# M55M1 register map
File version: 1.0
Registers are 32-bit, read-write, reset 0x0 unless marked. A register's access mark holds for its fields unless they carry their own. Offsets are from the block's base; [hi:lo] are bit positions; {n}, {i} and the like mark numbered series; 'fields as' and 'values as' point back to an identical list.

## SYS (part 1 of 3) — SYS Register Map
Base 0x40000000
0x00 SYS_PDID ro reset 0x551000 — Part Device Identification Number Register
  [31:0] PDID — Part Device Identification Number (Read Only). This register reflects device part number code. Software can read this register to identify which device is used.
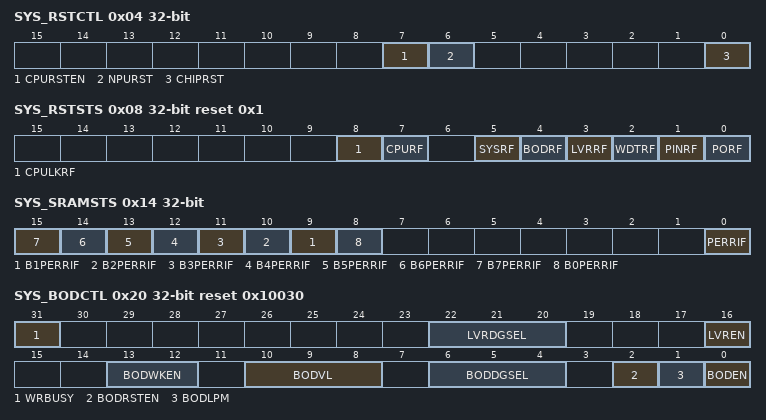
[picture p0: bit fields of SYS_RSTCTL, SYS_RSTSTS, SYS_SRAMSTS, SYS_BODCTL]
0x04 SYS_RSTCTL — System Reset Control Register
  [7] CPURSTEN — Processor Core Reset Enable (Write Protect). Setting this bit will only reset the processor core and Flash Memory Controller(FMC) when CPU execute WFI instruction. Note: This bit is write protected. Refer to the SYS_REGLCTL register..
    0=Processor core not reset when execute WFI instruction; 1=Processor core reset when execute WFI instruction
  [6] NPURST — NPU Reset (Write Protect). Setting this bit to 1 will generate a reset signal to the NPU. User needs to set this bit to 0 to release from reset state. Note 1: This bit is write protected. Refer to the SYS_REGLCTL register. Note 2: This bit is not retained when D0 power is turned off.
    0=NPU controller normal operation; 1=NPU controller reset
  [0] CHIPRST — Chip One-shot Reset (Write Protect). Setting this bit will reset the whole chip, including Processor core and all peripherals, and this bit will automatically return to 0 after the 2 clock cycles. The CHIPRST is same as the POR reset, all the chip controllers is reset and the chip setting from Flash are also reload. About the difference between CHIPRST and SYSRESETREQ(AIRCR[2]), please refer to section 6.2.2. Note: This bit is write protected. Refer to the SYS_REGLCTL register.
    0=Chip normal operation; 1=Chip one-shot reset
0x08 SYS_RSTSTS reset 0x1 — System Reset Status Register
  [8] CPULKRF — CPU Lockup Reset Flag. The CPU Lockup reset flag is set by hardware if Cortex-M55 lockup happened. Note 1: Write 1 to clear this bit to 0. Note 2: When CPU lockup happened under ICE is connected, this flag will set to 1 but chip will not reset. Note 3: This bit is not retained when D0 power is turned off.
    0=No reset from CPU lockup happened; 1=The Cortex-M55 lockup happened and chip is reset
  [7] CPURF — CPU Reset Flag. The CPU reset flag is set by hardware if software writes CPURST (SYS_RSTCTL[7]) 1 to reset the Cortex-M55 core and Flash Memory Controller (FMC). Note 1: Write 1 to clear this bit to 0. Note 2: This bit is not retained when D0 power is turned off.
    0=No reset from CPU; 1=The Cortex-M55 core and FMC are reset by software setting CPURST to 1
  [5] SYSRF — System Reset Flag. The system reset flag is set by the 'Reset Signal' from the Cortex-M55 core to indicate the previous reset source. Note 1: Write 1 to clear this bit to 0. Note 2: This bit is not retained when D0 power is turned off.
    0=No reset from the Cortex-M55; 1=The Cortex-M55 had issued the reset signal to reset the system by writing 1 to the bit SYSRESETREQ(AIRCR[2], Application Interrupt and Reset Control Register, address = 0xE000ED0C) in system control registers of Cortex-M55 core
  [4] BODRF — BOD Reset Flag. The BOD reset flag is set by the 'Reset Signal' from the Brown-out Detector to indicate the previous reset source. Note 1: Write 1 to clear this bit to 0. Note 2: This bit is not retained when D3 power is turned off.
    0=No reset from BOD; 1=The BOD had issued the reset signal to reset the system
  [3] LVRRF — LVR Reset Flag. The LVR reset flag is set by the 'Reset Signal' from the Low Voltage Reset Controller to indicate the previous reset source. Note 1: Write 1 to clear this bit to 0. Note 2: This bit is not retained when D3 power is turned off.
    0=No reset from LVR; 1=The LVR controller had issued the reset signal to reset the system
  [2] WDTRF — WDT Reset Flag. The WDT reset flag is set by the 'Reset Signal' from the Watchdog Timer or Window Watchdog Timer to indicate the previous reset source. Note 1: Write 1 to clear this bit to 0. Note 2: This bit is not retained when D2 power is turned off. Note 3: Watchdog Timer register RSTF(WDT_CTL[2]) bit is set if the system has been reset by WDT time-out reset. Window Watchdog Timer register WWDTRF(WWDT_STATUS[1]) bit is set if the system has been reset by WWDT time-out reset. Note 4: Extra Watchdog Timer register RSTF(EWDT_CTL[2]) bit is set if the system has been reset by EWDT time-out reset. Extra Window Watchdog Timer register WWDTRF(EWWDT_STATUS[1]) bit is set if the system has been reset by EWWDT time-out reset.
    0=No reset from watchdog timer or window watchdog timer; 1=The watchdog timer or window watchdog timer had issued the reset signal to reset the system
  [1] PINRF — nRESET Pin Reset Flag. The nRESET pin reset flag is set by the 'Reset Signal' from the nRESET Pin to indicate the previous reset source. Note 1: Write 1 to clear this bit to 0. Note 2: This bit is not retained when D4 power is turned off.
    0=No reset from nRESET pin; 1=Pin nRESET had issued the reset signal to reset the system
  [0] PORF — POR Reset Flag. The POR reset flag is set by the 'Reset Signal' from the Power-on Reset (POR) Controller or bit CHIPRST (SYS_RSTCTL[0]) to indicate the previous reset source. Note 1: Write 1 to clear this bit to 0. Note 2: This bit is not retained when D0 power is turned off.
    0=No reset from POR or CHIPRST; 1=Power-on Reset (POR) or CHIPRST had issued the reset signal to reset the system
0x0C SYS_VTORSET reset 0x100000 — VTOR Setting Register
  [31:7] VTORSET — VTOR Setting After SPD Wakeup (Write Protect). The value will be loaded to Vector Table Offset Register, which is at the address 0xE000ED08, when chip wake up and Perfomace Domain be turn off. Note 1: These bits are write protected. Refer to the SYS_REGLCTL register. Note 2: These bits are not retained when D4 power is turned off.
0x10 SYS_SRAMICTL — System SRAM Parity Error Interrupt Enable Control Register
  [0] PERRIEN — SRAM Parity Check Error Interrupt Enable Bit. Note: This bit is not retained when D0 power is turned off.
    0=SRAM parity check error interrupt Disabled; 1=SRAM parity check error interrupt Enabled
0x14 SYS_SRAMSTS (reset mask 0xFFFFFFF0) — System SRAM Parity Check Status Register
  [n+8] B{n}PERRIF ro (n=1..7) — SRAM Byte {n} Parity Check Error Flag (Read Only). This bit indicates the System SRAM byte {n} parity error occurred. Note 1: Write 1 to PERRIF for clear this bit to 0. Note 2: The default value depends on the content of SRAM. It is better to check this value before use it. If the default value is 1, it shall be cleared first. Note 3: This bit is not retained when D0 power is turned off.
    0=No System SRAM byte {n} parity error; 1=System SRAM byte {n} parity error occured
  [8] B0PERRIF ro — SRAM Byte 0 Parity Check Error Flag (Read Only). This bit indicates the System SRAM byte 0 parity error occurred. Note 1: Write 1 to PERRIF for clear this bit to 0.. Note 2: The default value depends on the content of SRAM. It is better to check this value before use it. If the default value is 1, it shall be cleared first. Note 3: This bit is not retained when D0 power is turned off.
    0=No System SRAM byte 0 parity error; 1=System SRAM byte 0 parity error occured
  [0] PERRIF — SRAM Parity Check Error Flag. This bit indicates the System SRAM byte 0 parity error occurred. Note 1: Write 1 to clear this bit to 0. Note 2: The default value depends on the content of SRAM. It is better to check this value before use it. If the default value is 1, it shall be cleared first. Note 3: This bit is not retained when D0 power is turned off.
    0=No System SRAM parity error; 1=System SRAM parity error occured
0x18 SYS_SRAMEADR ro — System SRAM Parity Error Address Register
  [31:0] ERRADDR — System SRAM Parity Error Address (Read Only). This register shows system SRAM parity error byte offset. Note: These bits are not retained when D0 power is turned off.
0x20 SYS_BODCTL reset 0x10030 — Brown-out Detector Control Register
  [31] WRBUSY ro — Write Busy Flag (Read Only). If SYS_BODCTL is written, this bit is asserted automatically by hardware, and is de-asserted when write procedure is finished.
    0=SYS_BODCTL register is ready for write operation; 1=SYS_BODCTL register is busy on the last write operation. Other write operations are ignored
  [22:20] LVRDGSEL — LVR Output De-glitch Time Select (Write Protect). Note 1: These bits are write protected. Refer to the SYS_REGLCTL register. Note 2: These bits are not retained when D0 power is turned off. Note 3: Because SCLK is invalid in Power-down mode, the de-glitch time must change to without de-glitch before system enters Power-down mode.
    0=Without de-glitch function; 1=4 system clock (SCLK); 2=8 system clock (SCLK); 3=16 system clock (SCLK); 4=32 system clock (SCLK); 5=64 system clock (SCLK); 6=128 system clock (SCLK); 7=256 system clock (SCLK)
  [16] LVREN — Low Voltage Reset Enable Bit (Write Protect). The LVR function resets the chip when the input power voltage is lower than LVR circuit setting. LVR function is enabled by default. Note 1: After enabling the bit, the LVR function will be active with 200us delay for LVR output stable (default). Note 2: This bit is write protected. Refer to the SYS_REGLCTL register. Note 3: Write operation is ignored when WRBUSY is high. Note 4: This bit is not retained when D3 power is turned off.
    0=Low Voltage Reset function Disabled; 1=Low Voltage Reset function Enabled
  [13:12] BODWKEN — Brown-out Detector Wake-Up Selection (Write Protect). Note 1: These bits are write protected. Refer to the SYS_REGLCTL register. Note 2: Write operation is ignored when WRBUSY is high. Note 3: These bits are not retained when D3 power is turned off.
    0=Brown-out Detector wake-up function Disable; 1=Brown-out Detector power rise wake-up function Enable; 2=Brown-out Detector power drop wake-up function Enable; 3=Brown-out Detector power rise and drop wake-up function Enable
  [10:8] BODVL — Brown-out Detector Threshold Voltage Selection (Write Protect). The default value is set by Flash controller user configuration register CBOV (CONFIG0 [23:21]). Note 1: These bits are write protected. Refer to the SYS_REGLCTL register. Note 2: Write operation is ignored when WRBUSY is high. Note 3: These bits are not retained when D3 power is turned off. Note 4: The default value is set by UCFG0[23:21].
    0=Brown-out Detector threshold voltage is 1.6V; 1=Brown-out Detector threshold voltage is 1.8V; 2=Brown-out Detector threshold voltage is 2.0V; 3=Brown-out Detector threshold voltage is 2.2V; 4=Brown-out Detector threshold voltage is 2.4V; 5=Brown-out Detector threshold voltage is 2.6V; 6=Brown-out Detector threshold voltage is 2.8V; 7=Brown-out Detector threshold voltage is 3.0V
  [6:4] BODDGSEL — Brown-out Detector Output De-glitch Time Select (Write Protect). Note 1: These bits are write protected. Refer to the SYS_REGLCTL register. Note 2: Write operation is ignored when WRBUSY is high. Note 3: These bits are not retained when D0 power is turned off. Note 4: Because SCLK is invalid in Power-down mode, the de-glitch time must change to LIRC before system enters Power-down mode. Note 5: If BODLPM(SYS_BODCTL[1]) is 1, the Brown-out Detector Output de-glitch circuit always uses LIRC clock even if BODDGSEL is not 000.
    0=BOD output is sampled by LIRC clock; 1=4 system clock (SCLK); 2=8 system clock (SCLK); 3=16 system clock (SCLK); 4=32 system clock (SCLK); 5=64 system clock (SCLK); 6=128 system clock (SCLK); 7=256 system clock (SCLK)
  [2] BODRSTEN — Brown-out Reset Enable Bit (Write Protect). The default value is set by Flash controller user configuration register CBORST(CONFIG0[20]) bit. Note 1: When the Brown-out Detector function is enabled (BODEN high) and BOD reset function is enabled (BODRSTEN high), BOD will assert a signal to reset chip when the detected voltage is lower than the threshold (BODOUT high). When the BOD function is enabled (BODEN high) and BOD interrupt function is enabled (BODRSTEN low), BOD will assert an interrupt if AVDD is lower than BODVL, BOD interrupt will keep till the BODIF set to 0. BOD interrupt can be blocked by disabling the NVIC BOD interrupt or disabling BOD function (setting BODEN low). Note 2: This bit is write protected. Refer to the SYS_REGLCTL register. Note 3: This bit is not retained when D3 power is turned off. Note 4: Write operation is ignored when WRBUSY is high. Note 5: The default value is set by inverse UCFG0[20]. Note 6: If D2PGEN(PMC_PWRCTL[2]) is 1 and enters Power-down mode, the brown-out reset function always keeps enabled even if BODRSTEN is 0.
    0=Brown-out 'INTERRUPT' function Enabled; 1=Brown-out 'RESET' function Enabled
  [1] BODLPM — Brown-out Detector Low Power Mode (Write Protect). Note 1: The BOD consumes about 10uA in normal mode, the low power mode can reduce the current to about 1/10 but slow the BOD response. Note 2: This bit is write protected. Refer to the SYS_REGLCTL register. Note 3: Write operation is ignored when WRBUSY is high. Note 4: This bit is not retained when D3 power is turned off.
    0=BOD operated in normal mode (default); 1=BOD Low Power mode Enabled
  [0] BODEN — Brown-out Detector Enable Bit (Write Protect). The default value is set by Flash controller user configuration register CBODEN (CONFIG0 [19]). Note 1: This bit is write protected. Refer to the SYS_REGLCTL register. Note 2: Write operation is ignored when WRBUSY is high. Note 3: This bit is not retained when D3 power is turned off. Note 4: The default value is set by inverse UCFG0[19].
    0=Brown-out Detector function Disabled; 1=Brown-out Detector function Enabled
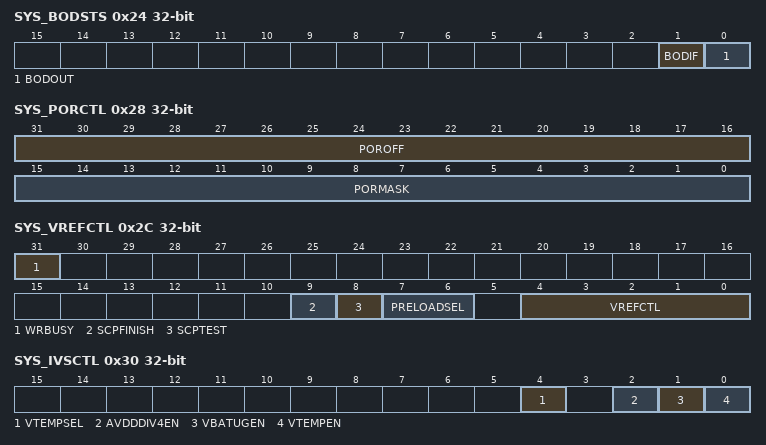
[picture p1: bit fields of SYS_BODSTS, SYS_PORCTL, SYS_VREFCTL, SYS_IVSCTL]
0x24 SYS_BODSTS — Brown-out Detector Status Register
  [1] BODIF — Brown-out Detector Interrupt Flag. Note 1: Write 1 to clear this bit to 0. Note 2: This bit is not retained when D1 power is turned off.
    0=Brown-out Detector does not detect any voltage draft at VDD down through or up through the voltage of BODVL(SYS_BODCTL[10:8]) setting; 1=When Brown-out Detector detects the VDD is dropped down through the voltage of BODVL(SYS_BODCTL[10:8]) setting or the VDD is raised up through the voltage of BODVL(SYS_BODCTL[10:8]) setting, this bit is set to 1 and the brown-out interrupt is requested if brown-out interrupt is enabled
  [0] BODOUT ro — Brown-out Detector Output Status (Read Only). It means the detected voltage is lower than BODVL(SYS_BODCTL[10:8]) setting. If the BODEN is 0, BOD function disabled, this bit always responds 0.
    0=Brown-out Detector output status is 0; 1=Brown-out Detector output status is 1
0x28 SYS_PORCTL — Power-on Reset Controller Register
  [31:16] POROFF — Power-on Reset Enable Bit (Write Protect). When powered on, the POR circuit generates a reset signal to reset the whole chip function, but noise on the power may cause the POR active again. User can disable internal POR circuit to avoid unpredictable noise to cause chip reset by writing 0x5AA5 to this field. The POR function will be active again when this field is set to another value or chip is reset by other reset source, including: nRESET, Watchdog, LVR reset, BOD reset, ICE reset command and the software-chip reset function. Note 1: These bits are write protected. Refer to the SYS_REGLCTL register. Note 2: These bits are not retained when D3 power is turned off.
  [15:0] PORMASK — Power-on Reset Mask Enable Bit (Write Protect). When powered on, the POR circuit generates a reset signal to reset the whole chip function, but noise on the power may cause the POR active again. User can mask internal POR signal to avoid unpredictable noise to cause chip reset by writing 0x5AA5 to this field. The POR function will be active again when this field is set to another value or chip is reset by other reset source, including: nRESET, Watchdog, LVR reset, BOD reset, ICE reset command and the software-chip reset function. Note 1: These bits are write protected. Refer to the SYS_REGLCTL register. Note 2: These bits are not retained when D3 power is turned off.
0x2C SYS_VREFCTL — VREF Control Register
  [31] WRBUSY ro — Write Busy Flag (Read Only). If SYS_VREFCTL is written, this bit is asserted automatically by hardware, and is de-asserted when write procedure is finished.
    0=SYS_VREFCTL register is ready for write operation; 1=SYS_VREFCTL register is busy on the last write operation. Other write operations are ignored
  [9] SCPFINISH ro — Short Circuit Protection Result (Read Only). Short circuit protection finish.
  [8] SCPTEST — Short Circuit Protection Test Pin (Write Protect). Note 1: This bit is write protected. Refer to the SYS_REGLCTL register. Note 2: Write operation is ignored when WRBUSY is high. Note 3: These bits are not retained when D2 power is turned off.
    0=Short circuit protection Disabled; 1=Short circuit protection Enabled
  [7:6] PRELOADSEL — Pre-load Timing Selection (Write Protect). Note 1: These bits are write protected. Refer to the SYS_REGLCTL register. Note 2: Write operation is ignored when WRBUSY is high. Note 3: These bits are not retained when D2 power is turned off.
    0=pre-load time is 480us for 1uF Capacitor, initial = 0v; 1=pre-load time is 2ms for 4.7uF Capacitor, initial = 0v; 2=pre-load time is 3ms for 1uF Capacitor, initial = 3.6v; 3=pre-load time is 15ms for 4.7uF Capacitor, initial = 3.6v
  [4:0] VREFCTL — VREF Control Bits (Write Protect). Note 1: These bits are write protected. Refer to the SYS_REGLCTL register. Note 2: Write operation is ignored when WRBUSY is high. Note 3: These bits are not retained when D2 power is turned off.
    0=VREF is from external pin; 3=VREF is internal 1.6V; 7=VREF is internal 2.048V; 11=VREF is internal 2.500V; 15=VREF is internal 3.072V
0x30 SYS_IVSCTL — Internal Voltage Source Control Register
  [4] VTEMPSEL — Temperature Sensor Slope Select Bit. This bit is used to select temperature sensor slope trend. Note 2: These bits are not retained when D0 power is turned off.
    0=Temperature sensor CTAT slope; 1=Temperature sensor PTAT slope
  [2] AVDDDIV4EN — AVDD divide 4 Enable Bit. This bit is used to enable/disable AVDD divide 4 function. Note 1: After this bit is set to 1, the value of AVDD divide 4 output voltage can be obtained from ADC conversion result. Note 2: These bits are not retained when D2 power is turned off.
    0=AVDD divide 4 function Disabled (default); 1=AVDD divide 4 function Enabled
  [1] VBATUGEN — VBAT Unity Gain Buffer Enable Bit. This bit is used to enable/disable VBAT unity gain buffer function. Note: After this bit is set to 1, the value of VBAT unity gain buffer output voltage can be obtained from ADC conversion result.
    0=VBAT unity gain buffer function Disabled (default); 1=VBAT unity gain buffer function Enabled
  [0] VTEMPEN — Temperature Sensor Enable Bit. This bit is used to enable/disable temperature sensor function. Note 1: After this bit is set to 1, the value of temperature sensor output can be obtained from ADC conversion result. Please refer to ADC chapter for details. Note 2: This bit is not retained when D0 power is turned off.
    0=Temperature sensor function Disabled (default); 1=Temperature sensor function Enabled
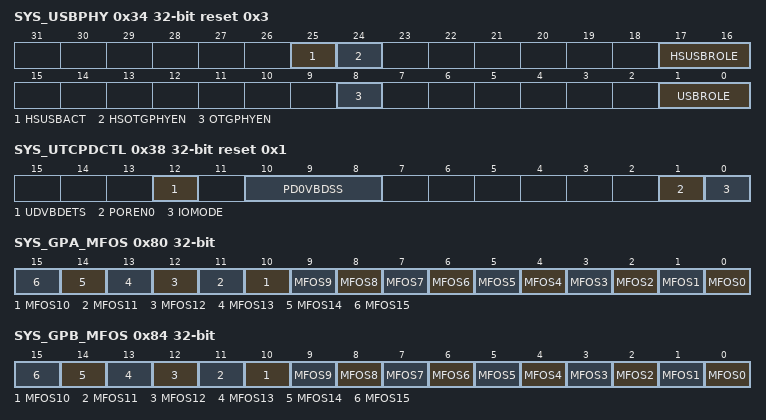
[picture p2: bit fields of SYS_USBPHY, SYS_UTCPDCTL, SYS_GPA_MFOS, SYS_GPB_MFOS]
0x34 SYS_USBPHY reset 0x3 — USB PHY Control Register
  [25] HSUSBACT — HSOTG PHY Active Control. This bit is used to control HSOTG PHY at reset state or active state. Note: After setting HSOTGPHYEN (SYS_USBPHY[24]) to enable HSOTG PHY, user should keep HSOTG PHY at reset mode at lease 10us before changing to active mode.
    0=HSOTG PHY at reset state; 1=HSOTG PHY at active state
  [24] HSOTGPHYEN — HSUSB OTG PHY Enable (Write Protect). This bit is used to enable/disable HSOTG PHY function. Note 1: This bit is write protected. Refer to the SYS_REGLCTL register. Note 2: This bit is not retained when D1 power is turned off.
    0=HSUSB OTG PHY function Disabled (default); 1=HSUSB OTG PHY function Enabled
  [17:16] HSUSBROLE — HSUSB Role Option (Write Protect). These two bits are used to select the role of HSUSB. Note 1: These bits are write protected. Refer to the SYS_REGLCTL register. Note 2: These bits are not retained when D1 power is turned off.
    0=Standard HSUSB Device mode; 1=Standard HSUSB Host mode; 2=ID dependent mode; 3=On-The-Go device mode
  [8] OTGPHYEN — USB OTG PHY Enable (Write Protect). This bit is used to enable/disable OTG PHY function. Note: This bit is not retained when D1 power is turned off.
    0=OTG PHY function Disabled (default); 1=OTG PHY function Enabled
  [1:0] USBROLE — USB Role Option (Write Protect). These two bits are used to select the role of USB. Note 1: These bits are write protected. Refer to the SYS_REGLCTL register. Note 2: These bits are not retained when D1 power is turned off.
    0=Standard USB Device mode; 1=Standard USB Host mode; 2=ID dependent mode; 3=On-The-Go device mode
0x38 SYS_UTCPDCTL reset 0x1 — UTCPD Control Register
  [12] UDVBDETS — UDC11 VBUS Detect Source Select. Note 1: Before use UDC11 function, UDVBDETS should be set and cannot change during UDC11 operating. Note 2: This bit is not retained when D3 power is turned off.
    0=UDC11 VBUS detect source from OTGPHY; 1=UDC11 VBUS detect source from VBDETSW0
  [10:8] PD0VBDSS — UTCPD0 VBUS Detect Source Select. UTCPD0 controller need a VBUS detect result to note if VBUS is connected. For NPD0~2 usage, ACMP can be another voltage detect method to detect VBUS pulg in or out. This bit field is used to select UTCPD0 VBUS detect source. And the selected result is VBDETSW0. Note 1: Before use UTCPD0 function, UDVBDETS should be set and cannot change during UTCPD0 operating. Note 2: This bit is not retained when D3 power is turned off.
    0=UTCPD0 VBUS detect source from UTCPD0 PHY; 1=UTCPD0 VBUS detect source from ACMP0 output; 2=UTCPD0 VBUS detect source from ACMP1 output; 3=UTCPD0 VBUS detect source from ACMP2 output
  [1] POREN0 — UTCPD0 Power-on Enable Bit. Note 1: user should set POREN0 to 1 after IOMODE is setting down. Note 2: This bit is not retained when D4 power is turned off.
    0=UTCPD0 PHY in reset mode; 1=UTCPD0 PHY in normal mode
  [0] IOMODE — UTCPD0 as I/O mode. This bit is used to define UTCPD0 CCx and CCDBx function. Note: This bit is not retained when D4 power is turned off.
    0=Pin as UTCPD0 CCx and CCDBx function; 1=Pin as general I/O function
0x40 SYS_DBUSCTL reset 0x1 — Data Bus Control Register
  [0] H2XBSTEN — Burst AHB2AXI Bridge access Enable Bit (Write Protect). Note 1: These bits are write protected. Refer to the SYS_REGLCTL register. Note 2: This bit is not retained when D0 power is turned off.
    0=Normal operating; 1=Force the attribute of all access from AHB to AXI modifiable
0x80 SYS_GPA_MFOS — GPIOA Multiple Function Output Select Register
  [all] fields
    0=Multiple function pin output mode type is Push-pull mode; 1=Multiple function pin output mode type is Open-drain mode
  [n] MFOS{n} (n=0..15) — GPIOA Pin[x] Multiple Function Pin Output Mode Select. This bit used to select multiple function pin output mode type for PA.x pin. Note 1: These bits are not retained when D2 power is turned off.
0x84 SYS_GPB_MFOS — GPIOB Multiple Function Output Select Register
  [all] fields
    values as the fields of SYS_GPA_MFOS
  [n] MFOS{n} (n=0..15) — GPIOB Pin[x] Multiple Function Pin Output Mode Select. This bit used to select multiple function pin output mode type for PB.x pin. Note: These bits are not retained when D2 power is turned off.
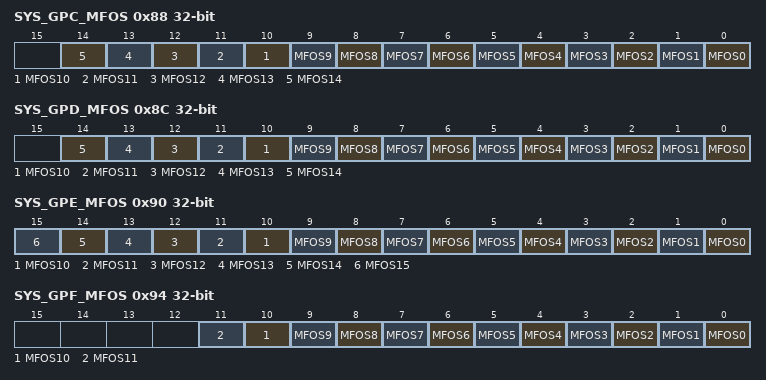
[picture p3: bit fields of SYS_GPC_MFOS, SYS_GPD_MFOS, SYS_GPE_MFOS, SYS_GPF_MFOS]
0x88 SYS_GPC_MFOS — GPIOC Multiple Function Output Select Register
  [all] fields
    values as the fields of SYS_GPA_MFOS
  [n] MFOS{n} (n=0..14) — GPIOC Pin[x] Multiple Function Pin Output Mode Select. This bit used to select multiple function pin output mode type for PC.x pin. Note: These bits are not retained when D2 power is turned off.
0x8C SYS_GPD_MFOS — GPIOD Multiple Function Output Select Register
  [all] fields
    values as the fields of SYS_GPA_MFOS
  [n] MFOS{n} (n=0..14) — GPIOD Pin[x] Multiple Function Pin Output Mode Select. This bit used to select multiple function pin output mode type for PD.x pin. Note: These bits are not retained when D2 power is turned off.
0x90 SYS_GPE_MFOS — GPIOE Multiple Function Output Select Register
  [all] fields
    values as the fields of SYS_GPA_MFOS
  [n] MFOS{n} (n=0..15) — GPIOE Pin[x] Multiple Function Pin Output Mode Select. This bit used to select multiple function pin output mode type for PE.x pin. Note: These bits are not retained when D2 power is turned off.
0x94 SYS_GPF_MFOS — GPIOF Multiple Function Output Select Register
  [all] fields
    values as the fields of SYS_GPA_MFOS
  [n] MFOS{n} (n=0..11) — GPIOF Pin[x] Multiple Function Pin Output Mode Select. This bit used to select multiple function pin output mode type for PF.x pin. Note: These bits are not retained when D2 power is turned off.
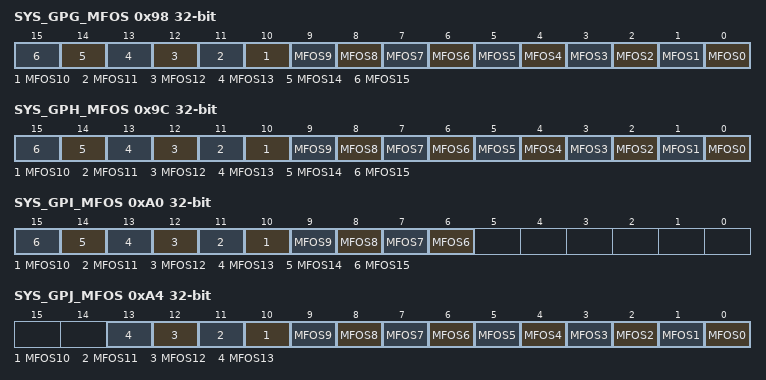
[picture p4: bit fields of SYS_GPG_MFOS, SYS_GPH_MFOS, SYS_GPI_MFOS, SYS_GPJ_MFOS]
0x98 SYS_GPG_MFOS — GPIOG Multiple Function Output Select Register
  [all] fields
    values as the fields of SYS_GPA_MFOS
  [n] MFOS{n} (n=0..15) — GPIOG Pin[x] Multiple Function Pin Output Mode Select. This bit used to select multiple function pin output mode type for PG.x pin. Note: These bits are not retained when D2 power is turned off.
0x9C SYS_GPH_MFOS — GPIOH Multiple Function Output Select Register
  [all] fields
    values as the fields of SYS_GPA_MFOS
  [n] MFOS{n} (n=0..15) — GPIOH Pin[x] Multiple Function Pin Output Mode Select. This bit used to select multiple function pin output mode type for PH.x pin. Note: These bits are not retained when D2 power is turned off.
0xA0 SYS_GPI_MFOS — GPIOI Multiple Function Output Select Register
  [all] fields
    values as the fields of SYS_GPA_MFOS
  [n] MFOS{n} (n=6..15) — GPIOI Pin[x] Multiple Function Pin Output Mode Select. This bit used to select multiple function pin output mode type for PI.x pin. Note: These bits are not retained when D2 power is turned off.
0xA4 SYS_GPJ_MFOS — GPIOJ Multiple Function Output Select Register
  [all] fields
    values as the fields of SYS_GPA_MFOS
  [n] MFOS{n} (n=0..13) — GPIOJ Pin[x] Multiple Function Pin Output Mode Select. This bit used to select multiple function pin output mode type for PJ.x pin. Note: These bits are not retained when D2 power is turned off.
0x100 SYS_REGLCTL — Register Lock Control Register
  [7:0] REGLCTL — Register Lock Control Code. Some registers have write-protection function. Writing these registers have to disable the protected function by writing the sequence value '59h', '16h', '88h' to this field. After this sequence is completed, the REGLCTL bit will be set to 1 and write-protection registers can be normal write. REGLCTL[0]. Register Lock Control Disable Index. Note: These bits are not retained when D2 power is turned off.
    0=Write-protection Enabled for writing protected registers. Any write to the protected register is ignored; 1=Write-protection Disabled for writing protected registers
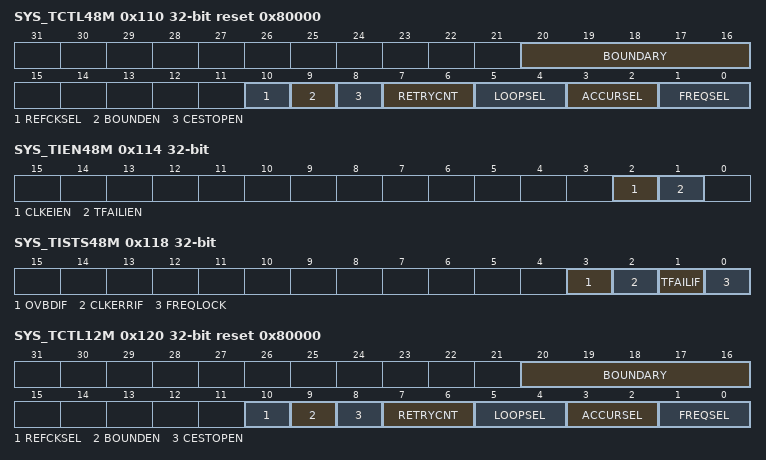
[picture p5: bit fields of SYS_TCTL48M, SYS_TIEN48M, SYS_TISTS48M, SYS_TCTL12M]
0x110 SYS_TCTL48M reset 0x80000 — HIRC 48M Trim Control Register
  [20:16] BOUNDARY — Boundary Selection. Fill the boundary range from 0x1 to 0x1F, 0x0 is reserved. Note: This field is effective only when the BOUNDEN(SYS_TCTL48M [9]) is enabled.
  [10] REFCKSEL — Reference Clock Selection
    0=HIRC48M trim reference clock is from external 32.768 kHz crystal oscillator; 1=HIRC48M trim reference clock is from internal USB synchronous mode
  [9] BOUNDEN — Boundary Enable Bit
    0=Boundary function Disabled; 1=Boundary function Enabled
  [8] CESTOPEN — Clock Error Stop Enable Bit
    0=Trim operation is kept going if clock is inaccurate; 1=Trim operation is stopped if clock is inaccurate
  [7:6] RETRYCNT — Trim Value Update Limitation Count. This field defines that how many times the auto trim circuit will try to update the HIRC48M trim value before the frequency of HIRC48M locked. Once the HIRC48M locked, the internal trim value update counter will be reset. If the trim value update counter reached this limitation value and frequency of HIRC48M is still not locked, the auto trim operation will be disabled and FREQSEL will be cleared to 00.
    0=Trim retry count limitation is 64 loops; 1=Trim retry count limitation is 128 loops; 2=Trim retry count limitation is 256 loops; 3=Trim retry count limitation is 512 loops
  [5:4] LOOPSEL — Trim Calculation Loop Selection. This field defines that trim value calculation is based on how many reference clocks. Note: For example, if LOOPSEL is set as 00, auto trim circuit will calculate trim value based on the average frequency difference in 4 clocks of reference clock.
    0=Trim value calculation is based on average difference in 4 clocks of reference clock; 1=Trim value calculation is based on average difference in 8 clocks of reference clock; 2=Trim value calculation is based on average difference in 16 clocks of reference clock; 3=Trim value calculation is based on average difference in 32 clocks of reference clock
  [3:2] ACCURSEL — Trim Accuracy Selection. This field indicates the target frequency accuracy of 48 MHz internal high speed RC oscillator (HIRC48M) auto trim.
    0=Accuracy is +-0.25% deviation within all temperature ranges; 1=Accuracy is +-0.50% deviation within all temperature ranges; 2=Accuracy is +-0.75% deviation within all temperature ranges; 3=Accuracy is +-1% deviation within all temperature ranges
  [1:0] FREQSEL — Trim Frequency Selection. This field indicates the target frequency of 48 MHz internal high speed RC oscillator (HIRC48M) auto trim. During auto trim operation, if clock error detected with CESTOPEN is set to 1 or trim retry limitation count reached, this field will be cleared to 00 automatically.
    0=Disable HIRC48M auto trim function; 1=Enable HIRC48M auto trim function and trim HIRC48M to 48 MHz
0x114 SYS_TIEN48M — HIRC 48M Trim Interrupt Enable Register
  [2] CLKEIEN — Clock Error Interrupt Enable Bit. This bit controls if CPU would get an interrupt while clock is inaccuracy during auto trim operation. If this bit is set to1, and CLKERRIF(SYS_TISTS48M [2]) is set during auto trim operation, an interrupt will be triggered to notify the clock frequency is inaccuracy.
    0=Disable CLKERRIF(SYS_TISTS48M [2]) status to trigger an interrupt to CPU; 1=Enable CLKERRIF(SYS_TISTS48M [2]) status to trigger an interrupt to CPU
  [1] TFAILIEN — Trim Failure Interrupt Enable Bit. This bit controls if an interrupt will be triggered while HIRC48M trim value update limitation count reached and HIRC48M frequency still not locked on target frequency set by FREQSEL(SYS_TCTL48M[1:0]). If this bit is high and TFAILIF(SYS_TSTS48M [1]) is set during auto trim operation, an interrupt will be triggered to notify that HIRC48M trim value update limitation count was reached.
    0=Disable TFAILIF(SYS_TISTS48M [1]) status to trigger an interrupt to CPU; 1=Enable TFAILIF(SYS_TISTS48M[1]) status to trigger an interrupt to CPU
0x118 SYS_TISTS48M — HIRC 48M Trim Interrupt Status Register
  [3] OVBDIF — Over Boundary Status. When the over boundary function is set, if there occurs the over boundary condition, this flag will be set. This is a status bit and doesn't trigger any interrupt. Note: Write 1 to clear this bit to 0.
    0=Over boundary condition did not occur; 1=Over boundary condition occurred
  [2] CLKERRIF — Clock Error Interrupt Status. When the frequency of 32.768 kHz external low speed crystal oscillator (LXT) or 48 MHz internal high speed RC oscillator (HIRC48M) is shift larger to unreasonable value, this bit will be set and to be an indicate that clock frequency is inaccuracy. Once this bit is set to 1, the auto trim operation stopped and FREQSEL(SYS_TCTL48M[1:0]) will be cleared to 00 by hardware automatically if CESTOPEN(SYS_TCTL48M[8]) is set to 1. If this bit is set and CLKEIEN(SYS_TIEN48M[2]) is high, an interrupt will be triggered to notify the clock frequency is inaccuracy. Note: Write 1 to clear this bit to 0.
    0=Clock frequency is accurate; 1=Clock frequency is inaccurate
  [1] TFAILIF — Trim Failure Interrupt Status. This bit indicates that HIRC48M trim value update limitation count reached and the HIRC48M clock frequency is still not locked. Once this bit is set, the auto trim operation stopped and FREQSEL(SYS_TCTL48M[1:0]) will be cleared to 00 by hardware automatically. If this bit is set and TFAILIEN(SYS_TIEN48M[1]) is high, an interrupt will be triggered to notify that HIRC48M trim value update limitation count was reached. Note: Write 1 to clear this bit to 0.
    0=Trim value update limitation count does not reach; 1=Trim value update limitation count reached and HIRC48M frequency still not locked
  [0] FREQLOCK — HIRC48M Frequency Lock Status. This bit indicates the HIRC48M frequency is locked. This is a status bit and doesn't trigger any interrupt. This bit will be set automatically, if the frequency is lock and the RC_TRIM is enabled. Note: Write 1 to clear this bit to 0.
    0=The internal high-speed oscillator frequency is not locked at 48 MHz; 1=The internal high-speed oscillator frequency locked at 48 MHz
0x120 SYS_TCTL12M reset 0x80000 — HIRC 12M Trim Control Register
  [20:16] BOUNDARY — Boundary Selection. Fill the boundary range from 0x1 to 0x1F, 0x0 is reserved. Note: This field is effective only when the BOUNDEN(SYS_TCTL12M[9]) is enabled.
  [10] REFCKSEL — Reference Clock Selection
    0=HIRC trim reference clock is from external 32.768 kHz crystal oscillator; 1=HIRC trim reference clock is from internal USB synchronous mode
  [9] BOUNDEN — Boundary Enable Bit
    0=Boundary function Disabled; 1=Boundary function Enabled
  [8] CESTOPEN — Clock Error Stop Enable Bit
    0=The trim operation keeps going if clock is inaccurate; 1=The trim operation is stopped if clock is inaccurate
  [7:6] RETRYCNT — Trim Value Update Limitation Count. This field defines that how many times the auto trim circuit will try to update the HIRC trim value before the frequency of HIRC locked. Once the HIRC locked, the internal trim value update counter will be reset. If the trim value update counter reached this limitation value and frequency of HIRC is still not locked, the auto trim operation will be disabled and FREQSEL will be cleared to 00.
    values as SYS_TCTL48M.RETRYCNT
  [5:4] LOOPSEL — Trim Calculation Loop Selection. This field defines that trim value calculation is based on how many reference clocks. Note: For example, if LOOPSEL is set as 00, auto trim circuit will calculate trim value based on the average frequency difference in 4 clocks of reference clock.
    values as SYS_TCTL48M.LOOPSEL
  [3:2] ACCURSEL — Trim Accuracy Selection. This field indicates the target frequency accuracy of 12 MHz internal high speed RC oscillator (IRC) auto trim.
    values as SYS_TCTL48M.ACCURSEL
  [1:0] FREQSEL — Trim Frequency Selection. This field indicates the target frequency of 12 MHz internal high speed RC oscillator (HIRC) auto trim. During auto trim operation, if clock error detected with CESTOPEN is set to 1 or trim retry limitation count reached, this field will be cleared to 00 automatically.
    0=Disable HIRC auto trim function; 1=Enable HIRC auto trim function and trim HIRC to 12 MHz
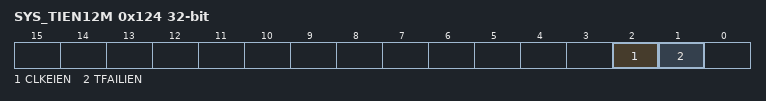
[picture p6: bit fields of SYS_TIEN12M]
0x124 SYS_TIEN12M — HIRC 12M Trim Interrupt Enable Register
  [2] CLKEIEN — Clock Error Interrupt Enable Bit. This bit controls if CPU would get an interrupt while clock is inaccuracy during auto trim operation. If this bit is set to1, and CLKERRIF(SYS_TISTS12M[2]) is set during auto trim operation, an interrupt will be triggered to notify the clock frequency is inaccuracy.
    0=Disable CLKERRIF(SYS_TISTS12M[2]) status to trigger an interrupt to CPU; 1=Enable CLKERRIF(SYS_TISTS12M[2]) status to trigger an interrupt to CPU
  [1] TFAILIEN — Trim Failure Interrupt Enable Bit. This bit controls if an interrupt will be triggered while HIRC trim value update limitation count reached and HIRC frequency still not locked on target frequency set by FREQSEL(SYS_TCTL12M[1:0]). If this bit is high and TFAILIF(SYS_TSTS12M[1]) is set during auto trim operation, an interrupt will be triggered to notify that HIRC trim value update limitation count was reached.
    0=Disable TFAILIF(SYS_TISTS12M[1]) status to trigger an interrupt to CPU; 1=Enable TFAILIF(SYS_TISTS12M[1]) status to trigger an interrupt to CPU
